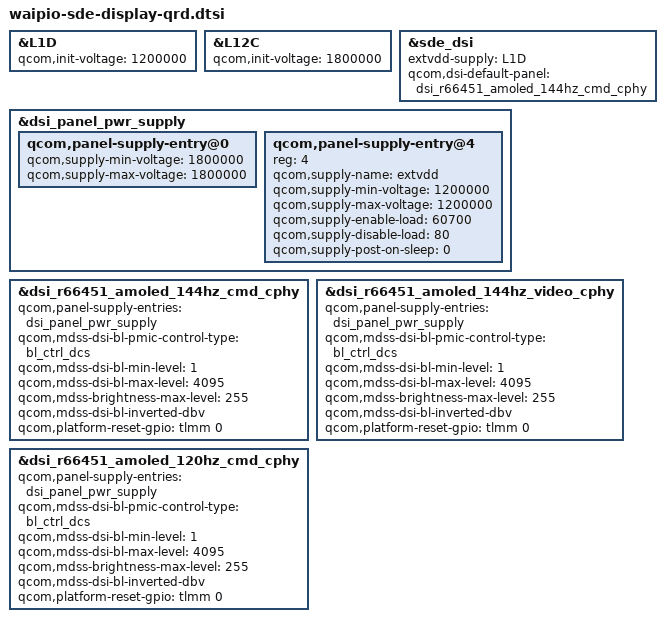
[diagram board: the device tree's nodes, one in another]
#include "waipio-sde-display.dtsi"

&L1D {
	qcom,init-voltage = <1200000>; /* panel ext vdd */
};

&L12C {
	qcom,init-voltage = <1800000>; /* panel vddio */
};

&sde_dsi {
	extvdd-supply = <&L1D>;
	qcom,dsi-default-panel = <&dsi_r66451_amoled_144hz_cmd_cphy>;
};

&dsi_panel_pwr_supply {
	qcom,panel-supply-entry@0 {
		qcom,supply-min-voltage = <1800000>;
		qcom,supply-max-voltage = <1800000>;
	};

	qcom,panel-supply-entry@4 {
		reg = <4>;
		qcom,supply-name = "extvdd";
		qcom,supply-min-voltage = <1200000>;
		qcom,supply-max-voltage = <1200000>;
		qcom,supply-enable-load = <60700>;
		qcom,supply-disable-load = <80>;
		qcom,supply-post-on-sleep = <0>;
	};
};

&dsi_r66451_amoled_144hz_cmd_cphy {
	qcom,panel-supply-entries = <&dsi_panel_pwr_supply>;
	qcom,mdss-dsi-bl-pmic-control-type = "bl_ctrl_dcs";
	qcom,mdss-dsi-bl-min-level = <1>;
	qcom,mdss-dsi-bl-max-level = <4095>;
	qcom,mdss-brightness-max-level = <255>;
	qcom,mdss-dsi-bl-inverted-dbv;
	qcom,platform-reset-gpio = <&tlmm 0 0>;
};

&dsi_r66451_amoled_144hz_video_cphy {
	qcom,panel-supply-entries = <&dsi_panel_pwr_supply>;
	qcom,mdss-dsi-bl-pmic-control-type = "bl_ctrl_dcs";
	qcom,mdss-dsi-bl-min-level = <1>;
	qcom,mdss-dsi-bl-max-level = <4095>;
	qcom,mdss-brightness-max-level = <255>;
	qcom,mdss-dsi-bl-inverted-dbv;
	qcom,platform-reset-gpio = <&tlmm 0 0>;
};

&dsi_r66451_amoled_120hz_cmd_cphy {
	qcom,panel-supply-entries = <&dsi_panel_pwr_supply>;
	qcom,mdss-dsi-bl-pmic-control-type = "bl_ctrl_dcs";
	qcom,mdss-dsi-bl-min-level = <1>;
	qcom,mdss-dsi-bl-max-level = <4095>;
	qcom,mdss-brightness-max-level = <255>;
	qcom,mdss-dsi-bl-inverted-dbv;
	qcom,platform-reset-gpio = <&tlmm 0 0>;
};
